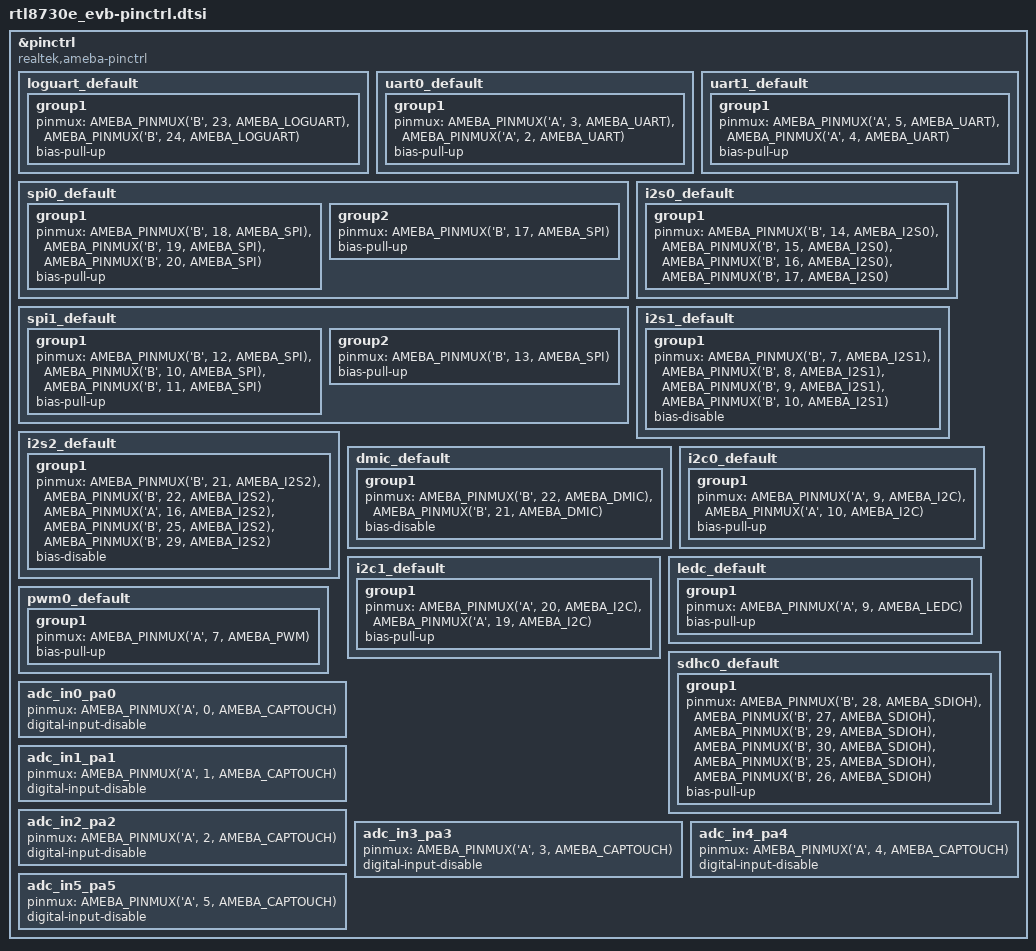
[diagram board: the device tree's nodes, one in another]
/*
 * Copyright (c) 2026 Realtek Semiconductor Corp.
 *
 * SPDX-License-Identifier: Apache-2.0
 */

#include <zephyr/dt-bindings/pinctrl/amebasmart-pinctrl.h>

&pinctrl {
	compatible = "realtek,ameba-pinctrl";

	/* PB23 is LOGUART RX, PB24 is LOGUART TX (both pull-up internally) */
	loguart_default: loguart_default {
		group1 {
			pinmux = <AMEBA_PINMUX('B', 23, AMEBA_LOGUART)>,  /* RX */
				 <AMEBA_PINMUX('B', 24, AMEBA_LOGUART)>;  /* TX */
			bias-pull-up;
		};
	};

	/* UART0: PA3=TX, PA2=RX (PINMUX_S0) */
	uart0_default: uart0_default {
		group1 {
			pinmux = <AMEBA_PINMUX('A', 3, AMEBA_UART)>,  /* TX */
				 <AMEBA_PINMUX('A', 2, AMEBA_UART)>;  /* RX */
			bias-pull-up;
		};
	};

	/* UART1: PA5=TX, PA4=RX (PINMUX_S0) */
	uart1_default: uart1_default {
		group1 {
			pinmux = <AMEBA_PINMUX('A', 5, AMEBA_UART)>,  /* TX */
				 <AMEBA_PINMUX('A', 4, AMEBA_UART)>;  /* RX */
			bias-pull-up;
		};
	};

	/*
	 * SPI0 (0x400E8000): PB17=CS, PB18=CLK, PB19=MOSI, PB20=MISO
	 */
	spi0_default: spi0_default {
		group1 {
			pinmux = <AMEBA_PINMUX('B', 18, AMEBA_SPI)>,
				 <AMEBA_PINMUX('B', 19, AMEBA_SPI)>,
				 <AMEBA_PINMUX('B', 20, AMEBA_SPI)>;
			bias-pull-up;
		};
		group2 {
			pinmux = <AMEBA_PINMUX('B', 17, AMEBA_SPI)>;
			bias-pull-up;
		};
	};

	/*
	 * SPI1 (0x400E9000): PB13=CS, PB12=CLK, PB10=MOSI, PB11=MISO
	 */
	spi1_default: spi1_default {
		group1 {
			pinmux = <AMEBA_PINMUX('B', 12, AMEBA_SPI)>,
				 <AMEBA_PINMUX('B', 10, AMEBA_SPI)>,
				 <AMEBA_PINMUX('B', 11, AMEBA_SPI)>;
			bias-pull-up;
		};
		group2 {
			pinmux = <AMEBA_PINMUX('B', 13, AMEBA_SPI)>;
			bias-pull-up;
		};
	};

	/* I2S0 / SPORT0 (0x4100D000). */
	i2s0_default: i2s0_default {
		group1 {
			pinmux = <AMEBA_PINMUX('B', 14, AMEBA_I2S0)>,  /* MCLK  */
				 <AMEBA_PINMUX('B', 15, AMEBA_I2S0)>,  /* BCLK  */
				 <AMEBA_PINMUX('B', 16, AMEBA_I2S0)>,  /* WS    */
				 <AMEBA_PINMUX('B', 17, AMEBA_I2S0)>;  /* DATA0 */
		};
	};

	/* I2S1 / SPORT1 (0x4100E000). */
	i2s1_default: i2s1_default {
		group1 {
			pinmux = <AMEBA_PINMUX('B',  7, AMEBA_I2S1)>,  /* MCLK  */
				 <AMEBA_PINMUX('B',  8, AMEBA_I2S1)>,  /* BCLK  */
				 <AMEBA_PINMUX('B',  9, AMEBA_I2S1)>,  /* WS    */
				 <AMEBA_PINMUX('B', 10, AMEBA_I2S1)>;  /* DATA0 */
			bias-disable;
		};
	};

	/* I2S2 / SPORT2 (0x4100F000), pinmux group1. */
	i2s2_default: i2s2_default {
		group1 {
			pinmux = <AMEBA_PINMUX('B', 21, AMEBA_I2S2)>,  /* BCLK  */
				 <AMEBA_PINMUX('B', 22, AMEBA_I2S2)>,  /* MCLK  */
				 <AMEBA_PINMUX('A', 16, AMEBA_I2S2)>,  /* WS    */
				 <AMEBA_PINMUX('B', 25, AMEBA_I2S2)>,  /* DOUT0 */
				 <AMEBA_PINMUX('B', 29, AMEBA_I2S2)>;  /* DIN0  */
			bias-disable;
		};
	};

	dmic_default: dmic_default {
		group1 {
			pinmux = <AMEBA_PINMUX('B', 22, AMEBA_DMIC)>,  /* CLK   */
				 <AMEBA_PINMUX('B', 21, AMEBA_DMIC)>;  /* DATA0 */
			bias-disable;
		};
	};

	i2c0_default: i2c0_default {
		group1 {
			pinmux = <AMEBA_PINMUX('A',  9, AMEBA_I2C)>,  /* SDA */
				 <AMEBA_PINMUX('A', 10, AMEBA_I2C)>;  /* SCL */
			bias-pull-up;
		};
	};

	i2c1_default: i2c1_default {
		group1 {
			pinmux = <AMEBA_PINMUX('A', 20, AMEBA_I2C)>,  /* SDA */
				 <AMEBA_PINMUX('A', 19, AMEBA_I2C)>;  /* SCL */
			bias-pull-up;
		};
	};

	/* LEDC serial output on PA9 (drives WS2812-style RGB LED chain) */
	ledc_default: ledc_default {
		group1 {
			pinmux = <AMEBA_PINMUX('A', 9, AMEBA_LEDC)>;
			bias-pull-up;
		};
	};

	pwm0_default: pwm0_default {
		group1 {
			pinmux = <AMEBA_PINMUX('A', 7, AMEBA_PWM)>; /* Channel 0 Output Pin */
			bias-pull-up;
		};
	};

	sdhc0_default: sdhc0_default {
		group1 {
			pinmux = <AMEBA_PINMUX('B', 28, AMEBA_SDIOH)>,  /* CLK */
				 <AMEBA_PINMUX('B', 27, AMEBA_SDIOH)>,  /* CMD */
				 <AMEBA_PINMUX('B', 29, AMEBA_SDIOH)>,  /* D0 */
				 <AMEBA_PINMUX('B', 30, AMEBA_SDIOH)>,  /* D1 */
				 <AMEBA_PINMUX('B', 25, AMEBA_SDIOH)>,  /* D2 */
				 <AMEBA_PINMUX('B', 26, AMEBA_SDIOH)>;  /* D3 */
			bias-pull-up;
		};
	};

	/*
	 * ADC external channels CH0-CH5 map to dedicated analog pads PA0-PA5.
	 * The ADC shares its analog front-end with captouch, so the pad uses the
	 * CAPTOUCH function with the digital input path disabled (matches the SDK
	 * analogin_init: Pinmux_Config(pin, PINMUX_FUNCTION_CAPTOUCH) +
	 * PAD_InputCtrl(DISABLE)).
	 */
	/omit-if-no-ref/ adc_in0_pa0: adc_in0_pa0 {
		pinmux = <AMEBA_PINMUX('A', 0, AMEBA_CAPTOUCH)>;
		digital-input-disable;
	};

	/omit-if-no-ref/ adc_in1_pa1: adc_in1_pa1 {
		pinmux = <AMEBA_PINMUX('A', 1, AMEBA_CAPTOUCH)>;
		digital-input-disable;
	};

	/omit-if-no-ref/ adc_in2_pa2: adc_in2_pa2 {
		pinmux = <AMEBA_PINMUX('A', 2, AMEBA_CAPTOUCH)>;
		digital-input-disable;
	};

	/omit-if-no-ref/ adc_in3_pa3: adc_in3_pa3 {
		pinmux = <AMEBA_PINMUX('A', 3, AMEBA_CAPTOUCH)>;
		digital-input-disable;
	};

	/omit-if-no-ref/ adc_in4_pa4: adc_in4_pa4 {
		pinmux = <AMEBA_PINMUX('A', 4, AMEBA_CAPTOUCH)>;
		digital-input-disable;
	};

	/omit-if-no-ref/ adc_in5_pa5: adc_in5_pa5 {
		pinmux = <AMEBA_PINMUX('A', 5, AMEBA_CAPTOUCH)>;
		digital-input-disable;
	};
};
